VERSION ""

NS_ :

BS_:

BU_: ECU1 ECU2

BA_DEF_ BO_ "VFrameFormat" ENUM "Standard","Extended";

VAL_TABLE_ LightStateVT 0 "Off" 1 "Parking" 2 "LowBeam" 3 "Auto";
VAL_TABLE_ TurnSignalVT 0 "Off" 1 "Left" 2 "Right" 3 "Reserved";

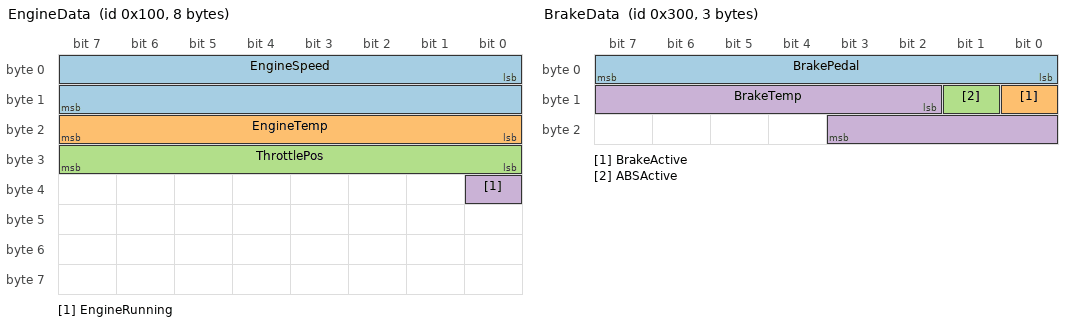
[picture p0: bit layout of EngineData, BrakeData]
BO_ 256 EngineData: 8 ECU1
 SG_ EngineSpeed : 0|16@1+ (0.25,0) [0|16383.75] "rpm" ECU2
 SG_ EngineTemp : 16|8@1+ (1,-40) [-40|215] "degC" ECU2
 SG_ ThrottlePos : 24|8@1+ (0.392157,0) [0|100] "%" ECU2
 SG_ EngineRunning : 32|1@1+ (1,0) [0|1] "" ECU2

BO_ 512 VehicleSpeed: 4 ECU1
 SG_ Speed : 0|16@1+ (0.01,0) [0|655.35] "km/h" ECU2
 SG_ Odometer : 16|16@1+ (1,0) [0|65535] "km" ECU2

BO_ 768 BrakeData: 3 ECU1
 SG_ BrakePedal : 0|8@1+ (0.392157,0) [0|100] "%" ECU2
 SG_ BrakeActive : 8|1@1+ (1,0) [0|1] "" ECU2
 SG_ ABSActive : 9|1@1+ (1,0) [0|1] "" ECU2
 SG_ BrakeTemp : 10|10@1+ (0.5,0) [0|511.5] "degC" ECU2

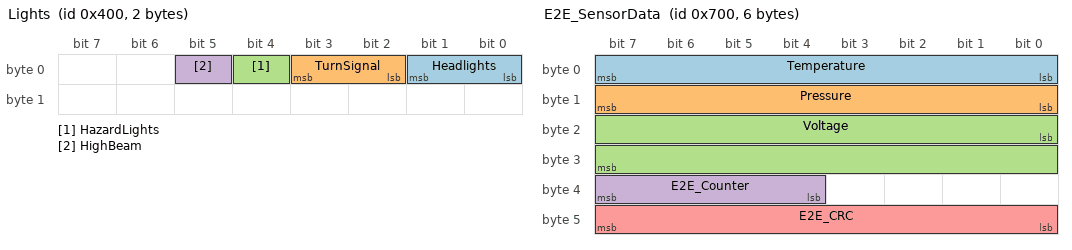
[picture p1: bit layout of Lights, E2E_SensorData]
BO_ 1024 Lights: 2 ECU2
 SG_ Headlights : 0|2@1+ (1,0) [0|3] "" ECU1
 SG_ TurnSignal : 2|2@1+ (1,0) [0|3] "" ECU1
 SG_ HazardLights : 4|1@1+ (1,0) [0|1] "" ECU1
 SG_ HighBeam : 5|1@1+ (1,0) [0|1] "" ECU1

BO_ 1536 DiagResponse: 8 ECU1
 SG_ DiagMux M : 0|4@1+ (1,0) [0|15] "" ECU2
 SG_ EngineCode m0 : 8|16@1+ (1,0) [0|65535] "" ECU2
 SG_ EngineHours m0 : 24|16@1+ (0.1,0) [0|6553.5] "h" ECU2
 SG_ BatteryVoltage m1 : 8|16@1+ (0.01,0) [0|655.35] "V" ECU2
 SG_ BatteryCurrent m1 : 24|16@1- (0.1,0) [-3276.8|3276.7] "A" ECU2
 SG_ OilPressure m2 : 8|8@1+ (4,0) [0|1020] "kPa" ECU2
 SG_ OilTemp m2 : 16|8@1+ (1,-40) [-40|215] "degC" ECU2

BO_ 1280 BitMatrix: 8 ECU1
 SG_ Bit00 : 0|1@1+ (1,0) [0|1] "" ECU2
 SG_ Bit01 : 1|1@1+ (1,0) [0|1] "" ECU2
 SG_ Bit02 : 2|1@1+ (1,0) [0|1] "" ECU2
 SG_ Bit03 : 3|1@1+ (1,0) [0|1] "" ECU2
 SG_ Bit04 : 4|1@1+ (1,0) [0|1] "" ECU2
 SG_ Bit05 : 5|1@1+ (1,0) [0|1] "" ECU2
 SG_ Bit06 : 6|1@1+ (1,0) [0|1] "" ECU2
 SG_ Bit07 : 7|1@1+ (1,0) [0|1] "" ECU2
 SG_ Bit08 : 8|1@1+ (1,0) [0|1] "" ECU2
 SG_ Bit09 : 9|1@1+ (1,0) [0|1] "" ECU2
 SG_ Bit10 : 10|1@1+ (1,0) [0|1] "" ECU2
 SG_ Bit11 : 11|1@1+ (1,0) [0|1] "" ECU2
 SG_ Bit12 : 12|1@1+ (1,0) [0|1] "" ECU2
 SG_ Bit13 : 13|1@1+ (1,0) [0|1] "" ECU2
 SG_ Bit14 : 14|1@1+ (1,0) [0|1] "" ECU2
 SG_ Bit15 : 15|1@1+ (1,0) [0|1] "" ECU2
 SG_ Bit16 : 16|1@1+ (1,0) [0|1] "" ECU2
 SG_ Bit17 : 17|1@1+ (1,0) [0|1] "" ECU2
 SG_ Bit18 : 18|1@1+ (1,0) [0|1] "" ECU2
 SG_ Bit19 : 19|1@1+ (1,0) [0|1] "" ECU2
 SG_ Bit20 : 20|1@1+ (1,0) [0|1] "" ECU2
 SG_ Bit21 : 21|1@1+ (1,0) [0|1] "" ECU2
 SG_ Bit22 : 22|1@1+ (1,0) [0|1] "" ECU2
 SG_ Bit23 : 23|1@1+ (1,0) [0|1] "" ECU2
 SG_ Bit24 : 24|1@1+ (1,0) [0|1] "" ECU2
 SG_ Bit25 : 25|1@1+ (1,0) [0|1] "" ECU2
 SG_ Bit26 : 26|1@1+ (1,0) [0|1] "" ECU2
 SG_ Bit27 : 27|1@1+ (1,0) [0|1] "" ECU2
 SG_ Bit28 : 28|1@1+ (1,0) [0|1] "" ECU2
 SG_ Bit29 : 29|1@1+ (1,0) [0|1] "" ECU2
 SG_ Bit30 : 30|1@1+ (1,0) [0|1] "" ECU2
 SG_ Bit31 : 31|1@1+ (1,0) [0|1] "" ECU2
 SG_ Bit32 : 32|1@1+ (1,0) [0|1] "" ECU2
 SG_ Bit33 : 33|1@1+ (1,0) [0|1] "" ECU2
 SG_ Bit34 : 34|1@1+ (1,0) [0|1] "" ECU2
 SG_ Bit35 : 35|1@1+ (1,0) [0|1] "" ECU2
 SG_ Bit36 : 36|1@1+ (1,0) [0|1] "" ECU2
 SG_ Bit37 : 37|1@1+ (1,0) [0|1] "" ECU2
 SG_ Bit38 : 38|1@1+ (1,0) [0|1] "" ECU2
 SG_ Bit39 : 39|1@1+ (1,0) [0|1] "" ECU2
 SG_ Bit40 : 40|1@1+ (1,0) [0|1] "" ECU2
 SG_ Bit41 : 41|1@1+ (1,0) [0|1] "" ECU2
 SG_ Bit42 : 42|1@1+ (1,0) [0|1] "" ECU2
 SG_ Bit43 : 43|1@1+ (1,0) [0|1] "" ECU2
 SG_ Bit44 : 44|1@1+ (1,0) [0|1] "" ECU2
 SG_ Bit45 : 45|1@1+ (1,0) [0|1] "" ECU2
 SG_ Bit46 : 46|1@1+ (1,0) [0|1] "" ECU2
 SG_ Bit47 : 47|1@1+ (1,0) [0|1] "" ECU2
 SG_ Bit48 : 48|1@1+ (1,0) [0|1] "" ECU2
 SG_ Bit49 : 49|1@1+ (1,0) [0|1] "" ECU2
 SG_ Bit50 : 50|1@1+ (1,0) [0|1] "" ECU2
 SG_ Bit51 : 51|1@1+ (1,0) [0|1] "" ECU2
 SG_ Bit52 : 52|1@1+ (1,0) [0|1] "" ECU2
 SG_ Bit53 : 53|1@1+ (1,0) [0|1] "" ECU2
 SG_ Bit54 : 54|1@1+ (1,0) [0|1] "" ECU2
 SG_ Bit55 : 55|1@1+ (1,0) [0|1] "" ECU2
 SG_ Bit56 : 56|1@1+ (1,0) [0|1] "" ECU2
 SG_ Bit57 : 57|1@1+ (1,0) [0|1] "" ECU2
 SG_ Bit58 : 58|1@1+ (1,0) [0|1] "" ECU2
 SG_ Bit59 : 59|1@1+ (1,0) [0|1] "" ECU2
 SG_ Bit60 : 60|1@1+ (1,0) [0|1] "" ECU2
 SG_ Bit61 : 61|1@1+ (1,0) [0|1] "" ECU2
 SG_ Bit62 : 62|1@1+ (1,0) [0|1] "" ECU2
 SG_ Bit63 : 63|1@1+ (1,0) [0|1] "" ECU2

 BO_ 1792 E2E_SensorData: 6 ECU1
 SG_ Temperature : 0|8@1+ (0.5,-40) [-40|87.5] "degC" ECU2
 SG_ Pressure : 8|8@1+ (1,0) [0|255] "kPa" ECU2
 SG_ Voltage : 16|16@1+ (0.001,0) [0|65.535] "V" ECU2
 SG_ E2E_Counter : 36|4@1+ (1,0) [0|14] "" ECU2
 SG_ E2E_CRC : 40|8@1+ (1,0) [0|255] "" ECU2

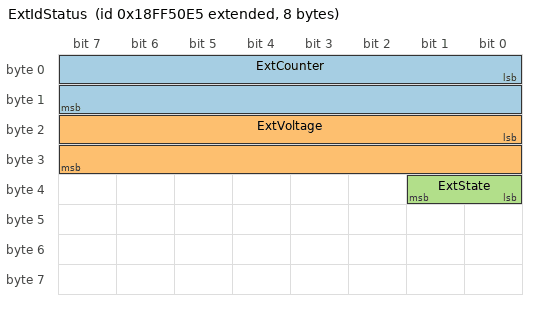
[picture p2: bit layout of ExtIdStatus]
BO_ 2566869221 ExtIdStatus: 8 ECU1
 SG_ ExtCounter : 0|16@1+ (1,0) [0|65535] "" ECU2
 SG_ ExtVoltage : 16|16@1+ (0.001,0) [0|65.535] "V" ECU2
 SG_ ExtState : 32|2@1+ (1,0) [0|3] "" ECU2
BA_ "VFrameFormat" BO_ 2566869221 1;

BO_ 1600 CanFdPayload: 64 ECU2
 SG_ Block0 : 0|16@1+ (1,0) [0|65535] "" ECU1
 SG_ Block1 : 16|16@1+ (1,0) [0|65535] "" ECU1
 SG_ Block2 : 32|16@1+ (1,0) [0|65535] "" ECU1
 SG_ Block3 : 48|16@1+ (1,0) [0|65535] "" ECU1
 SG_ Block4 : 64|16@1+ (1,0) [0|65535] "" ECU1
 SG_ Block5 : 80|16@1+ (1,0) [0|65535] "" ECU1
 SG_ Block6 : 96|16@1+ (1,0) [0|65535] "" ECU1
 SG_ Block7 : 112|16@1+ (1,0) [0|65535] "" ECU1

BO_ 1601 CanFdLen12: 12 ECU2
 SG_ Fd12_A : 0|32@1+ (1,0) [0|4294967295] "" ECU1
 SG_ Fd12_B : 32|32@1+ (1,0) [0|4294967295] "" ECU1
 SG_ Fd12_C : 64|32@1+ (1,0) [0|4294967295] "" ECU1

BO_ 1602 CanFdLen16: 16 ECU2
 SG_ Fd16_A : 0|64@1+ (1,0) [0|18446744073709551615] "" ECU1
 SG_ Fd16_B : 64|64@1+ (1,0) [0|18446744073709551615] "" ECU1

BO_ 1603 CanFdLen20: 20 ECU2
 SG_ Fd20_A : 0|64@1+ (1,0) [0|18446744073709551615] "" ECU1
 SG_ Fd20_B : 64|64@1+ (1,0) [0|18446744073709551615] "" ECU1
 SG_ Fd20_C : 128|32@1+ (1,0) [0|4294967295] "" ECU1

BO_ 1604 CanFdLen24: 24 ECU2
 SG_ Fd24_A : 0|64@1+ (1,0) [0|18446744073709551615] "" ECU1
 SG_ Fd24_B : 64|64@1+ (1,0) [0|18446744073709551615] "" ECU1
 SG_ Fd24_C : 128|64@1+ (1,0) [0|18446744073709551615] "" ECU1

BO_ 1605 CanFdLen32: 32 ECU2
 SG_ Fd32_A : 0|64@1+ (1,0) [0|18446744073709551615] "" ECU1
 SG_ Fd32_B : 64|64@1+ (1,0) [0|18446744073709551615] "" ECU1
 SG_ Fd32_C : 128|64@1+ (1,0) [0|18446744073709551615] "" ECU1
 SG_ Fd32_D : 192|64@1+ (1,0) [0|18446744073709551615] "" ECU1

BO_ 1606 CanFdLen48: 48 ECU2
 SG_ Fd48_A : 0|64@1+ (1,0) [0|18446744073709551615] "" ECU1
 SG_ Fd48_B : 64|64@1+ (1,0) [0|18446744073709551615] "" ECU1
 SG_ Fd48_C : 128|64@1+ (1,0) [0|18446744073709551615] "" ECU1
 SG_ Fd48_D : 192|64@1+ (1,0) [0|18446744073709551615] "" ECU1
 SG_ Fd48_E : 256|64@1+ (1,0) [0|18446744073709551615] "" ECU1
 SG_ Fd48_F : 320|64@1+ (1,0) [0|18446744073709551615] "" ECU1

BO_ 1607 CanFdLen64: 64 ECU2
 SG_ Fd64_A : 0|64@1+ (1,0) [0|18446744073709551615] "" ECU1
 SG_ Fd64_B : 64|64@1+ (1,0) [0|18446744073709551615] "" ECU1
 SG_ Fd64_C : 128|64@1+ (1,0) [0|18446744073709551615] "" ECU1
 SG_ Fd64_D : 192|64@1+ (1,0) [0|18446744073709551615] "" ECU1
 SG_ Fd64_E : 256|64@1+ (1,0) [0|18446744073709551615] "" ECU1
 SG_ Fd64_F : 320|64@1+ (1,0) [0|18446744073709551615] "" ECU1
 SG_ Fd64_G : 384|64@1+ (1,0) [0|18446744073709551615] "" ECU1
 SG_ Fd64_H : 448|64@1+ (1,0) [0|18446744073709551615] "" ECU1

VAL_ 1024 Headlights 0 "Off" 1 "Parking" 2 "LowBeam" 3 "Auto";
VAL_ 1024 TurnSignal 0 "Off" 1 "Left" 2 "Right" 3 "Reserved";
VAL_ 1024 HazardLights 0 "Inactive" 1 "Active";
VAL_ 1024 HighBeam 0 "Off" 1 "On";

CM_ BO_ 256 "Engine sensor data at 100ms cycle";
CM_ BO_ 512 "Vehicle speed and odometer";
CM_ BO_ 768 "Brake system status";
CM_ BO_ 1024 "Lighting control";
CM_ BO_ 1280 "64 x 1-bit signals for decode performance testing";
CM_ BO_ 1792 "E2E-protected sensor data (4-byte payload + counter nibble + CRC-8)";
CM_ BO_ 2566869221 "Extended ID example (29-bit).";
CM_ BO_ 1600 "CAN FD example with 64-byte payload.";
CM_ BO_ 1601 "CAN FD example (DLC 9 -> 12 bytes).";
CM_ BO_ 1602 "CAN FD example (DLC 10 -> 16 bytes).";
CM_ BO_ 1603 "CAN FD example (DLC 11 -> 20 bytes).";
CM_ BO_ 1604 "CAN FD example (DLC 12 -> 24 bytes).";
CM_ BO_ 1605 "CAN FD example (DLC 13 -> 32 bytes).";
CM_ BO_ 1606 "CAN FD example (DLC 14 -> 48 bytes).";
CM_ BO_ 1607 "CAN FD example (DLC 15 -> 64 bytes).";
CM_ SG_ 1792 E2E_Counter "Rolling 4-bit counter appended by E2E plugin (process_tx)";
CM_ SG_ 1792 E2E_CRC "CRC-8/MAXIM over payload + counter, appended by E2E plugin";
CM_ SG_ 256 EngineSpeed "Engine crankshaft speed";
CM_ SG_ 256 EngineTemp "Engine coolant temperature";
CM_ SG_ 512 Speed "Vehicle ground speed";
CM_ SG_ 768 BrakePedal "Brake pedal position percentage";

BA_DEF_ BO_ "GenMsgCycleTime" INT 0 10000;
BA_DEF_ SG_ "GenSigStartValue" FLOAT 0 100000;
BA_ "GenMsgCycleTime" BO_ 256 100;
BA_ "GenMsgCycleTime" BO_ 512 200;
BA_ "GenMsgCycleTime" BO_ 768 50;
BA_ "GenMsgCycleTime" BO_ 1024 500;
BA_ "GenMsgCycleTime" BO_ 1280 1;
BA_ "GenMsgCycleTime" BO_ 1792 100;
BA_ "GenSigStartValue" SG_ 1792 Temperature 85;
BA_ "GenSigStartValue" SG_ 1792 Pressure 101;
BA_ "GenSigStartValue" SG_ 1792 Voltage 12000;
BA_ "GenSigStartValue" SG_ 1792 E2E_Counter 0;
BA_ "GenSigStartValue" SG_ 1792 E2E_CRC 0;
BA_ "GenSigStartValue" SG_ 256 EngineSpeed 3200;
BA_ "GenSigStartValue" SG_ 256 EngineTemp 130;
BA_ "GenSigStartValue" SG_ 256 ThrottlePos 38;
BA_ "GenSigStartValue" SG_ 256 EngineRunning 1;
BA_ "GenSigStartValue" SG_ 512 Speed 6000;
BA_ "GenSigStartValue" SG_ 512 Odometer 12345;
BA_ "GenSigStartValue" SG_ 768 BrakePedal 0;
BA_ "GenSigStartValue" SG_ 768 BrakeActive 0;
BA_ "GenSigStartValue" SG_ 768 ABSActive 0;
BA_ "GenSigStartValue" SG_ 768 BrakeTemp 50;
BA_ "GenSigStartValue" SG_ 1024 Headlights 1;
BA_ "GenSigStartValue" SG_ 1024 TurnSignal 0;
BA_ "GenSigStartValue" SG_ 1024 HazardLights 0;
BA_ "GenSigStartValue" SG_ 1024 HighBeam 0;
